# ICC_445 register map
Vendor: Texas Instruments
Peripheral module from a debugger description file (folder msp430).
Registers are 16-bit, read-write, no defined reset value unless marked. A register's access mark holds for its fields unless they carry their own. Offsets are as the file gives them; lines under a group give offsets from that group; [hi:lo] are bit positions; {n}, {i} and the like mark numbered series; 'fields as' and 'values as' point back to an identical list; <NAME> marks a mode.

## ICC
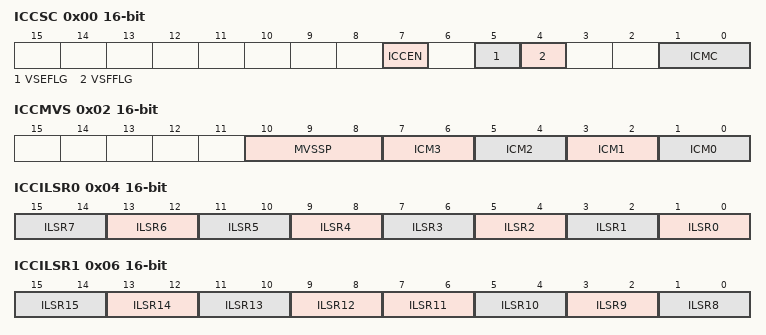
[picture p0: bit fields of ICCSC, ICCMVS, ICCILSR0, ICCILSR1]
0x00 ICCSC access per field
  [7] ICCEN rw — ICC enable
    0=ICC module disabled; 1=ICC module enabled
  [5] VSEFLG ro — Virtual stack empty flag.This bit indicates whether or not the virtual stack is empty. It is automatically updated when the stack is pushed or popped.
    0=Stack has valid data; 1=Stack has no valid data
  [4] VSFFLG ro — Virtual stack full flag This bit indicates whether or not the virtual stack is full. It is automatically updated when the stack is pushed or popped.
    0=ICCMVS register is not full; 1=ICCMVS register is full
  [1:0] ICMC ro — Current Interrupt Compare Mask of virtual stack specifies the current ICM at the top of virtual stack If ICM[1:0] is less than the priority level (ILSRx[1:0]) of the new interrupt, the corresponding source is sent to the CPU. Note that the ICMC is the element stack that the stack pointer is pointing to.
0x02 ICCMVS ro
  [10:8] MVSSP — MVS stack pointer indicate register
    0=000b = Stack empty; 1=001b = ICM0 affected; 2=010b = ICM0 and ICM1 affected; 3=011b = ICM0, ICM1, and ICM2 affected; 4=100b = ICM0, ICM1, ICM2, and ICM3 affected. Also means the stack is full.
  [2n+1:2n] ICM{n} (n=0..3) — Interrupt compare mask virtual stack position {n} This field is the virtual stack register for ICM{n}.
0x04 ICCILSR0
  [2n+1:2n] ILSR{n} (n=0..7) — Sets the interrupt level for this interrupt source. Maskable interrupt sources only. See the device-specific data sheet to determine the interrupt source for each ILSRx bit.
0x06 ICCILSR1
  [2n-15:2n-16] ILSR{n} (n=12..15) — Sets the interrupt level for this interrupt source. Maskable interrupt sources only. See the device-specific data sheet to determine the interrupt source for each ILSRxx bit.
  [7:6] ILSR11 — Sets the interrupt level for this interrupt source. Maskable interrupt sources only. See the device-specific data sheet to determine the interrupt source for each ILSRxx bit
  [5:4] ILSR10 — Sets the interrupt level for this interrupt source. Maskable interrupt sources only. See the device-specific data sheet to determine the interrupt source for each ILSRxx bit.
  [3:2] ILSR9 — Sets the interrupt level for this interrupt source. Maskable interrupt sources only. See the device-specific data sheet to determine the interrupt source for each ILSRxx bit.
  [1:0] ILSR8 — Sets the interrupt level for this interrupt source. Maskable interrupt sources only. See the device-specific data sheet to determine the interrupt source for each ILSRxx bit.
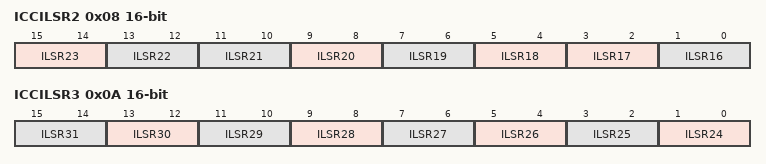
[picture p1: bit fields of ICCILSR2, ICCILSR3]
0x08 ICCILSR2
  [15:14] ILSR23 — Sets the interrupt level for this interrupt source. Maskable interrupt sources only. See the device-specific data sheet to determine the interrupt source for each
  [13:12] ILSR22 — Sets the interrupt level for this interrupt source. Maskable interrupt sources only. See the device-specific data sheet to determine the interrupt source for each
  [2n-31:2n-32] ILSR{n} (n=18..21) — Sets the interrupt level for this interrupt source. Maskable interrupt sources only. See the device-specific data sheet to determine the interrupt source for each ILSRxx bit.
  [3:2] ILSR17 — Sets the interrupt level for this interrupt source. Maskable interrupt sources only. See the device-specific data sheet to determine the interrupt source for each ILSRxx bit
  [1:0] ILSR16 — Sets the interrupt level for this interrupt source. Maskable interrupt sources only. See the device-specific data sheet to determine the interrupt source for each ILSRxx bit.
0x0A ICCILSR3
  [2n-47:2n-48] ILSR{n} (n=24..31) — Sets the interrupt level for this interrupt source. Maskable interrupt sources only. See the device-specific data sheet to determine the interrupt source for each ILSRxx bit.
